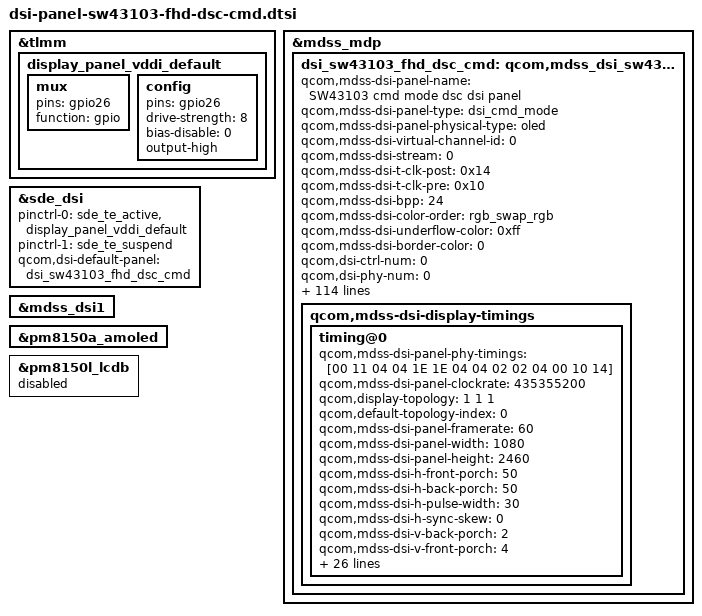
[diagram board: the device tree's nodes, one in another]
/* Copyright (c) 2014, Code Aurora Forum. All rights reserved.
 *
 * This program is free software; you can redistribute it and/or modify
 * it under the terms of the GNU General Public License version 2 and
 * only version 2 as published by the Free Software Foundation.
 *
 * This program is distributed in the hope that it will be useful,
 * but WITHOUT ANY WARRANTY; without even the implied warranty of
 * MERCHANTABILITY or FITNESS FOR A PARTICULAR PURPOSE.  See the
 * GNU General Public License for more details.
 */

&tlmm {
	display_panel_vddi_default: display_panel_vddi_default {
		mux {
			pins = "gpio26";
			function = "gpio";
		};

		config {
			pins = "gpio26";
			drive-strength = <8>;
			bias-disable = <0>;
			output-high;
		};
	};
};

&mdss_mdp {
    dsi_sw43103_fhd_dsc_cmd: qcom,mdss_dsi_sw43103_fhd_dsc_cmd {
		qcom,mdss-dsi-panel-name = "SW43103 cmd mode dsc dsi panel";
		qcom,mdss-dsi-panel-type = "dsi_cmd_mode";
		qcom,mdss-dsi-panel-physical-type = "oled";
		qcom,mdss-dsi-virtual-channel-id = <0>;
		qcom,mdss-dsi-stream = <0>;
		qcom,mdss-dsi-t-clk-post = <0x14>;
		qcom,mdss-dsi-t-clk-pre = <0x10>;
		qcom,mdss-dsi-bpp = <24>;
		qcom,mdss-dsi-color-order = "rgb_swap_rgb";
		qcom,mdss-dsi-underflow-color = <0xff>;
		qcom,mdss-dsi-border-color = <0>;
		qcom,dsi-ctrl-num = <0>;
		qcom,dsi-phy-num = <0>;
		qcom,dsi-select-clocks = "mux_byte_clk0", "mux_pixel_clk0";
		qcom,mdss-dsi-traffic-mode = "burst_mode";
		qcom,mdss-dsi-lane-map = "lane_map_0123";
		qcom,mdss-dsi-bllp-eof-power-mode;
		qcom,mdss-dsi-bllp-power-mode;
		qcom,mdss-dsi-lane-0-state;
		qcom,mdss-dsi-lane-1-state;
		qcom,mdss-dsi-lane-2-state;
		qcom,mdss-dsi-lane-3-state;
		qcom,mdss-dsi-reset-sequence = <1 10>, <0 2>, <1 10>;
		qcom,mdss-dsi-dma-trigger = "trigger_sw";
		qcom,mdss-dsi-mdp-trigger = "none";
		qcom,mdss-dsi-te-pin-select = <1>;
		qcom,panel-te-source = <0>;
		qcom,mdss-dsi-wr-mem-start = <0x2c>;
		qcom,mdss-dsi-wr-mem-continue = <0x3c>;
		qcom,mdss-dsi-te-dcs-command = <1>;
		//qcom,mdss-dsi-te-check-enable;
		//qcom,mdss-dsi-te-using-te-pin;
		//qcom,mdss-dsi-lp11-init;
		qcom,mdss-dsi-tx-eot-append;
		qcom,ulps-enabled;
		qcom,null-insertion-enabled;

		qcom,mdss-pan-physical-width-dimension = <70>;
		qcom,mdss-pan-physical-height-dimension = <159>;

		/* Brightness Map List */
		lge,blmap = <
			0
			6 11 17 22 28 34 39 45 50 56 62 67 73 79 84
			90 95 101 107 112 118 123 129 135 140 146 151 157 163 168
			174 179 185 191 196 202 208 213 219 224 230 236 241 247 252
			258 264 269 275 280 286 292 297 303 308 314 320 325 331 336
			342 348 353 359 365 370 376 381 387 393 398 404 409 415 421
			426 432 437 443 449 454 460 465 471 477 482 488 494 499 505
			510 516 522 527 533 538 544 550 555 561 566 572 578 583 589
			594 600 606 611 617 623 628 634 639 645 651 656 662 667 673
			679 684 690 695 701 707 712 718 723 729 735 740 746 752 757
			763 768 774 780 785 791 796 802 808 813 819 824 830 836 841
			847 852 858 864 869 875 880 886 892 897 903 909 914 920 925
			931 937 942 948 953 959 965 970 976 981 987 993 998 1004 1009
			1015 1021 1026 1032 1038 1043 1049 1054 1060 1066 1071 1077 1082 1088 1094
			1099 1105 1110 1116 1122 1127 1133 1138 1144 1150 1155 1161 1167 1172 1178
			1183 1189 1195 1200 1206 1211 1217 1223 1228 1234 1239 1245 1251 1256 1262
			1267 1273 1279 1284 1290 1295 1301 1307 1312 1318 1324 1329 1335 1340 1346
			1352 1357 1363 1368 1374 1380 1385 1391 1396 1402 1408 1413 1419 1424 1430
			1436 1441 1447 1453 1458 1464 1469 1475 1481 1486 1492 1497 1503 1509 1514
			1520 1525 1531 1537 1542 1548 1553 1559 1565 1570 1576 1582 1587 1593 1598
			1604 1610 1615 1621 1626 1632 1638 1643 1649 1654 1660 1666 1671 1677 1682
			1688 1694 1699 1705 1711 1716 1722 1727 1733 1739 1744 1750 1755 1761 1767
			1772 1778 1783 1789 1795 1800 1806 1811 1817 1823 1828 1834 1839 1845 1851
			1856 1862 1868 1873 1879 1884 1890 1896 1901 1907 1912 1918 1924 1929 1935
			1940 1946 1952 1957 1963 1968 1974 1980 1985 1991 1997 2002 2008 2013 2019
			2025 2030 2036 2041 2047
		>;
		lge,blmap-ve = <
			0
			5 5 5 5 5 5 5 5 5 5 6 8 9 10 11 13 14 15 16 18
			19 20 22 23 24 25 27 28 29 30 32 33 34 35 37 38 43 48 52 57
			62 67 71 76 81 86 90 95 100 105 109 114 119 124 128 133 138 143 147 152
			157 163 168 174 180 185 191 197 202 208 214 219 225 231 236 242 248 253 259 265
			270 273 277 280 293 296 299 302 305 308 312 315 318 321 324 327 330 333 336 339
			342 345 349 352 355 358 361 364 368 371 375 378 382 386 389 393 397 400 404 407
			411 415 418 422 425 429 433 436 440 444 447 451 454 458 467 475 484 492 501 509
			518 522 530 539 547 556 564 573 581 590 599 607 616 624 633 641 650 658 672 680
			687 695 703 711 718 726 734 741 749 757 765 772 780 788 795 803 811 818 826 834
			842 849 857 862 866 871 875 880 884 889 893 898 902 907 912 916 921 925 930 934
			939 943 948 952 957 961 966 971 976 981 986 991 996 1001 1006 1011 1016 1021 1026 1032
			1037 1042 1047 1052 1057 1062 1067 1072 1077 1082 1087 1092 1122 1152 1182 1212 1242 1271 1301 1331
			1361 1391 1421 1451 1481 1511 1541 1571 1601 1630 1660 1690 1720 1750 1780 1782 1783 1785 1786 1788
			1789 1791 1792 1794 1795 1797 1798 1800 1801 1803 1804 1806 1807 1809 1810 1812 1815 1817 1819 1822
			1824 1826 1829 1831 1833 1836 1838 1840 1843 1845 1848 1850 1853 1856 1858 1861 1864 1866 1869 1872
			1874 1877 1880 1882 1885 1888 1890 1893 1896 1898 1901 1904 1906 1909 1912 1914 1917 1920 1922 1925
			1928 1930 1933 1936 1938 1941 1944 1946 1949 1952 1954 1957 1960 1962 1965 1968 1970 1973 1976 1978
			1981 1984 1986 1989 1992 1994 1997 2000 2002 2005 2008 2011 2013 2016 2019 2022 2025 2027 2030 2033
			2036 2039 2041 2044 2047
		>;
		lge,blmap-ex = <
			0
			10 10 10 10 10 10 10 10 127 129 131 133 135 137 139 142 144 146 148 150
			152 154 156 158 160 162 164 166 168 171 173 175 177 179 181 183 189 194 200 205
			211 216 222 227 233 238 244 249 255 261 266 272 277 283 288 294 299 305 310 316
			321 327 333 338 344 349 355 360 366 371 377 382 388 393 399 407 415 423 431 439
			447 455 463 471 479 487 495 503 511 519 527 535 543 551 559 567 575 581 587 594
			600 606 612 619 625 631 637 643 650 656 662 668 675 681 687 695 704 712 721 729
			738 746 754 763 771 780 788 796 805 813 822 830 839 847 847 847 847 847 847 847
			856 866 875 884 893 903 912 921 930 940 949 958 967 977 986 995 1004 1014 1023 1023
			1023 1023 1023 1023 1023 1023 1023 1023 1023 1023 1023 1023 1023 1023 1023 1023 1023 1023 1023 1023
			1023 1023 1023 1023 1023 1023 1023 1023 1023 1023 1023 1023 1023 1023 1023 1023 1023 1023 1023 1023
			1023 1023 1023 1023 1023 1023 1023 1023 1023 1023 1023 1023 1023 1023 1023 1023 1023 1023 1023 1023
			1023 1023 1023 1023 1023 1023 1023 1023 1023 1023 1023 1023 1023 1023 1023 1023 1023 1023 1023 1023
			1023 1023 1023 1023 1023 1023 1023 1023 1023 1023 1023 1023 1023 1023 1023
		>;
		lge,blmap-hdr = <
			0
			5 5 5 5 5 5 5 5 5 5 6 8 9 10 11 13 14 15 16 18
			19 20 22 23 24 25 27 28 29 30 32 33 34 35 37 38 43 48 52 57
			62 67 71 76 81 86 90 95 100 105 109 114 119 124 128 133 138 143 147 152
			157 163 168 174 180 185 191 197 202 208 214 219 225 231 236 242 248 253 259 265
			270 273 277 280 293 296 299 302 305 308 312 315 318 321 324 327 330 333 336 339
			342 345 349 352 355 358 361 364 368 371 375 378 382 386 389 393 397 400 404 407
			411 415 418 422 425 429 433 436 440 444 447 451 454 458 467 475 484 492 501 509
			518 522 530 539 547 556 564 573 581 590 599 607 616 624 633 641 650 658 672 680
			687 695 703 711 718 726 734 741 749 757 765 772 780 788 795 803 811 818 826 834
			842 849 857 862 866 871 875 880 884 889 893 898 902 907 912 916 921 925 930 934
			939 943 948 952 957 961 966 971 976 981 986 991 996 1001 1006 1011 1016 1021 1026 1032
			1037 1042 1047 1052 1057 1062 1067 1072 1077 1082 1087 1092 1122 1152 1182 1212 1242 1271 1301 1331
			1361 1391 1421 1451 1481 1511 1541 1571 1601 1630 1660 1690 1720 1750 1780 1782 1783 1785 1786 1788
			1789 1791 1792 1794 1795 1797 1798 1800 1801 1803 1804 1806 1807 1809 1810 1812 1815 1817 1819 1822
			1824 1826 1829 1831 1833 1836 1838 1840 1843 1845 1848 1850 1853 1856 1858 1861 1864 1866 1869 1872
			1874 1877 1880 1882 1885 1888 1890 1893 1896 1898 1901 1904 1906 1909 1912 1914 1917 1920 1922 1925
			1928 1930 1933 1936 1938 1941 1944 1946 1949 1952 1954 1957 1960 1962 1965 1968 1970 1973 1976 1978
			1981 1984 1986 1989 1992 1994 1997 2000 2002 2005 2008 2011 2013 2016 2019 2022 2025 2027 2030 2033
			2036 2039 2041 2044 2047
		>;

		/* AOD */
		lge,use-ambient;
		lge,aod-interface-data = "partial", "partial", "partial";
		lge,update-pps-in-lp-mode;
		lge,mdss-dsi-nolp-command = [
			05 01 00 00 00 00 01 28
			05 01 00 00 78 00 01 13
			05 01 00 00 00 00 01 29
		];
		lge,mdss-dsi-nolp-command-state = "dsi_lp_mode";
		lge,mdss-dsi-lp2-command = [
			05 01 00 00 00 00 01 28
			05 01 00 00 78 00 01 12
			05 01 00 00 00 00 01 29
		];
		lge,mdss-dsi-lp2-command-state = "dsi_lp_mode";

		lge,use-color-manager;
		lge,color-manager-default-status = <1>;
		lge,mdss-dsi-color-manager-mode-table = <0 1>, <1 1>, <2 1>, <3 1>;

		/* FP LHBM */
		lge,use-fp-lhbm;
		lge,mdss-dsi-fp-lhbm-command = [
			39 01 00 00 00 00 02 B0 A3
			39 01 00 00 00 00 04 EE 02 00 00
			39 01 00 00 00 00 02 B0 A5
			39 01 00 00 00 00 0C CD 10 12 01 5A 90 00 00 00 00 00 62//Green Circle
			39 01 00 00 00 00 02 B0 A1
			39 01 00 00 00 00 0B 55 08 08 72 D4 1C 61 0A 90 04 00//FPS On
			39 01 00 00 00 00 03 51 07 FF
			/*
			mipi.write 0x39 0xCD 0x00 //FP_SHAPE 0: Rectangle
			mipi.write 0x39 0xCD 0x10 //FP_SHAPE 1: circle
			mipi.write 0x39 0xCD 0x10 0x17 //White
			mipi.write 0x39 0xCD 0x00 0x14 //Red
			mipi.write 0x39 0xCD 0x00 0x12 //Green
			mipi.write 0x39 0xCD 0x00 0x11 //Blue
			mipi.write 0x39 0xCD 0x00 0x00 //Black
			*/
		];
		lge,mdss-dsi-fp-lhbm-command-state = "dsi_hs_mode";

		lge,mdss-dsi-fp-lhbm-exit-command = [
			39 01 00 00 00 00 02 B0 A1
			39 01 00 00 00 00 0B 55 08 00 //FPS Off
			39 01 00 00 00 00 03 51 06 F4
		];
		lge,mdss-dsi-fp-lhbm-exit-command-state = "dsi_hs_mode";

		/* Screen Color Control */
		lge,mdss-dsi-disp-ctrl-command-1 = [
		    15 01 00 00 00 00 02 B0 A1
			15 01 00 00 00 00 02 53 00
		];
		lge,mdss-dsi-disp-ctrl-command-1-state = "dsi_hs_mode";

		lge,mdss-dsi-wb-default-command = [
			15 01 00 00 00 00 02 B0 A4
			39 01 00 00 00 00 0B B4 00 03 05 AF 03 05 AF 03 05 AF
			39 01 00 00 00 00 1C B5 00 FF 80 00 80 00 80 00 80 00 FF 80 00 80 00 80 00 80 00 FF 80 00 80 00 80 00 80
		];
		lge,mdss-dsi-wb-default-command-state = "dsi_hs_mode";

		lge,digital-gamma-cmds-dummy = [
			15 01 00 00 00 00 02 B0 A4
			39 01 00 00 00 00 0B B4 00 03 05 AF 03 05 AF 03 05 AF
			39 01 00 00 00 00 1C B5 00 FF 80 00 80 00 80 00 80 00 FF 80 00 80 00 80 00 80 00 FF 80 00 80 00 80 00 80
		];
		lge,digital-gamma-cmds-dummy-command = "dsi_hs_mode";

		lge,mdss-dsi-saturation-command = [
		    15 01 00 00 00 00 02 B0 A4
			39 01 00 00 00 00 0D B7 80 80 80 80 80 80 80 80 80 80 80 80
			39 01 00 00 00 00 0D B8 80 80 80 80 80 80 80 80 80 80 80 80
			39 01 00 00 00 00 0D B9 40 40 40 3A 3A 3D 40 40 40 40 40 40
			39 01 00 00 00 00 0D BA 80 80 80 80 80 80 80 80 80 80 80 80
		];
		lge,mdss-dsi-saturation-command-state = "dsi_hs_mode";

		lge,mdss-dsi-hue-command = [
		    15 01 00 00 00 00 02 B0 A4
			39 01 00 00 00 00 0D BB 80 80 80 80 80 80 80 80 80 80 80 80
		];
		lge,mdss-dsi-hue-command-state = "dsi_hs_mode";

		lge,mdss-dsi-sharpness-command = [
		    15 01 00 00 00 00 02 B0 A4
			39 01 00 00 00 00 0C B2 89 1F 1F 88 24 68 22 20 04 00 00
		];
		lge,mdss-dsi-sharpness-command-state = "dsi_hs_mode";

		lge,mdss-dsi-cm-cinema = [
			15 01 00 00 00 00 02 B0 A4
			39 01 00 00 00 00 0B B4 00 03 05 AF 03 01 6B 03 01 6B
			39 01 00 00 00 00 1C B5 00 FF 80 00 80 00 80 00 80 00 F2 7E FC 7B F9 78 F6 75 00 C9 79 F2 6B E4 5E D7 50
			39 01 00 00 00 00 0D B7 80 80 80 80 80 80 80 80 80 80 80 80
			39 01 00 00 00 00 0D B8 80 80 80 80 89 80 80 80 80 80 80 80
			39 01 00 00 00 00 0D B9 2F 2D 2D 37 3D 35 3A 3A 3A 3A 35 2E
			39 01 00 00 00 00 0D BA 80 80 80 80 88 80 80 80 80 80 80 7D
			39 01 00 00 00 00 0D BB 5D 5A 7B 8B 75 70 80 80 80 80 83 8C
		];
		lge,mdss-dsi-cm-cinema-state = "dsi_hs_mode";

		lge,mdss-dsi-cm-sports = [
			15 01 00 00 00 00 02 B0 A4
			39 01 00 00 00 00 0B B4 00 03 01 6B 03 01 6B 03 05 AF
			39 01 00 00 00 00 1C B5 00 DD 7B F7 73 EF 6A E6 62 00 F2 7E FC 7B F9 78 F6 75 00 FF 80 00 80 00 80 00 80
		];
		lge,mdss-dsi-cm-sports-state = "dsi_hs_mode";

		lge,mdss-dsi-cm-game = [
			15 01 00 00 00 00 02 B0 A4
			39 01 00 00 00 00 0B B4 00 03 01 6B 03 01 6B 03 05 AF
			39 01 00 00 00 00 1C B5 00 F0 7E FC 7A F8 76 F4 72 00 FB 7F FF 7E FE 7E FD 7D 00 FF 80 00 80 00 80 00 80
		];
		lge,mdss-dsi-cm-game-state = "dsi_hs_mode";

		lge,mdss-dsi-cm-photo = [
			15 01 00 00 00 00 02 B0 A4
			39 01 00 00 00 00 0B B4 00 03 05 AF 03 01 6B 03 01 6B
			39 01 00 00 00 00 1C B5 00 FF 80 00 80 00 80 00 80 00 F2 7E FC 7B F9 78 F6 75 00 C9 79 F2 6B E4 5E D7 50
			39 01 00 00 00 00 0D B7 80 80 80 80 80 80 80 80 80 80 80 80
			39 01 00 00 00 00 0D B8 80 80 7D 78 80 80 80 80 80 80 80 80
			39 01 00 00 00 00 0D B9 25 2A 2D 2D 2F 4D 2D 3B 40 40 40 40
			39 01 00 00 00 00 0D BA 76 6C 6C 6D 6D 80 70 80 80 80 80 80
			39 01 00 00 00 00 0D BB 65 4D 62 78 78 78 80 6D 6D 80 80 80
		];
		lge,mdss-dsi-cm-photo-state = "dsi_hs_mode";

		lge,mdss-dsi-cm-web = [
			15 01 00 00 00 00 02 B0 A4
			39 01 00 00 00 00 0B B4 00 03 05 AF 03 01 6B 03 01 6B
			39 01 00 00 00 00 1C B5 00 FF 80 00 80 00 80 00 80 00 F2 7E FC 7B F9 78 F6 75 00 C9 79 F2 6B E4 5E D7 50
			39 01 00 00 00 00 0D B7 80 80 80 80 80 80 80 80 80 80 80 80
			39 01 00 00 00 00 0D B8 80 80 80 80 80 80 80 80 80 80 80 80
			39 01 00 00 00 00 0D B9 25 29 27 26 27 39 35 2F 2B 2B 20 28
			39 01 00 00 00 00 0D BA 79 70 70 70 75 70 70 70 63 63 63 63
			39 01 00 00 00 00 0D BB 66 70 8A 8A 67 67 80 95 95 80 8B 78
		];
		lge,mdss-dsi-cm-web-state = "dsi_hs_mode";

		/* Video Enahnacement */
		lge,mdss-dsi-ve-on-command = [
		    15 01 00 00 00 00 02 B0 A1
			15 01 00 00 00 00 02 53 14
			39 01 00 00 00 00 02 55 28
			15 01 00 00 00 00 02 B0 A4
			39 01 00 00 00 00 0C B2 89 3F 2F 88 88 88 22 20 04 00 00
			39 01 00 00 00 00 0D B7 80 80 80 80 80 80 80 80 80 80 80 80
			39 01 00 00 00 00 0D B8 80 80 80 80 80 80 80 80 80 80 80 80
			39 01 00 00 00 00 0D B9 46 46 46 46 46 46 46 46 46 46 46 46
			39 01 00 00 00 00 0D BA 80 80 80 80 80 80 80 80 80 80 80 80
			39 01 00 00 00 00 0D BB 80 80 80 80 80 80 80 80 80 80 80 80
		];
		lge,mdss-dsi-ve-on-command-state = "dsi_hs_mode";

		lge,mdss-dsi-ve-off-command = [
		    15 01 00 00 00 00 02 B0 A1
			39 01 00 00 00 00 02 55 08
		];
		lge,mdss-dsi-ve-off-command-state = "dsi_hs_mode";

		lge,use-irc-ctrl;
		lge,mdss-dsi-irc-command = [
			15 01 00 00 00 00 02 B0 A5
			39 01 00 00 00 00 08 B1 60 C0 00 00 00 10 FF
		];
		lge,mdss-dsi-irc-command-state = "dsi_hs_mode";

		lge,use-ace-ctrl;
		lge,default-ace-mode = <0>;
		lge,mdss-dsi-ace-tune-command = [
			15 01 00 00 00 00 02 B0 A4
			39 01 00 00 00 00 0C B2 89 3F 2F 88 88 88 33 20 04 00 00
			39 01 00 00 00 00 07 B3 00 80 FF 88 08 93
			15 01 00 00 00 00 02 B0 A1
			15 01 00 00 00 00 02 53 14
			39 01 00 00 00 00 02 55 28
		];
		lge,mdss-dsi-ace-restore-command = [
			15 01 00 00 00 00 02 B0 A1
			15 01 00 00 00 00 02 53 00
			39 01 00 00 00 00 02 55 08
		];
		lge,mdss-dsi-ace-command-state = "dsi_hs_mode";

		lge,use-touch-vsync-enable;
		lge,mdss-dsi-touch-vsync-enable-command = [
			15 01 00 00 00 00 02 B0 A6
			39 01 00 00 00 00 05 FC 00 00 41 40
		];
		lge,mdss-dsi-touch-vsync-enable-command-state = "dsi_hs_mode";

		qcom,mdss-dsi-display-timings {
			timing@0{
				qcom,mdss-dsi-panel-phy-timings = [00 11 04 04 1E 1E 04 04 02 02 04 00 10 14];
				qcom,mdss-dsi-panel-clockrate = <435355200>;
				qcom,display-topology = <1 1 1>;
				qcom,default-topology-index = <0>;
				qcom,mdss-dsi-panel-framerate = <60>;
				qcom,mdss-dsi-panel-width = <1080>;
				qcom,mdss-dsi-panel-height = <2460>;
				qcom,mdss-dsi-h-front-porch = <50>;
				qcom,mdss-dsi-h-back-porch = <50>;
				qcom,mdss-dsi-h-pulse-width = <30>;
				qcom,mdss-dsi-h-sync-skew = <0>;
				qcom,mdss-dsi-v-back-porch = <2>;
				qcom,mdss-dsi-v-front-porch = <4>;
				qcom,mdss-dsi-v-pulse-width = <2>;
				qcom,mdss-dsi-h-left-border = <0>;
				qcom,mdss-dsi-h-right-border = <0>;
				qcom,mdss-dsi-v-top-border = <0>;
				qcom,mdss-dsi-v-bottom-border = <0>;
				qcom,mdss-dsi-h-sync-pulse = <0>;
				//qcom,mdss-mdp-transfer-time-us = <15000>;

				qcom,mdss-dsi-on-command = [
					15 01 00 00 00 00 02 B0 A1
					15 01 00 00 00 00 02 53 00
					15 01 00 00 00 00 02 55 08
					15 01 00 00 00 00 02 3D 00
					15 01 00 00 00 00 02 35 00
					39 01 00 00 00 00 05 2A 00 00 04 37
					39 01 00 00 00 00 05 2B 00 00 09 9B
					39 01 00 00 00 00 05 30 00 00 09 9B
					39 01 00 00 00 00 05 31 00 00 04 37

					//IP Setting
					15 01 00 00 00 00 02 B0 A6 //level6 TOP_CTRL
					15 01 00 00 00 00 02 F7 AC //OTP auto load off afet Sleep out
					15 01 00 00 00 00 02 B0 A1 //level1TOP_CTRL
					15 01 00 00 00 00 02 B0 CA //Manufacturer Command Protect
					05 01 00 00 78 00 01 11    //Sleep Out

					15 01 00 00 00 00 02 B0 A6
					39 01 00 00 00 00 05 FC 00 00 41 40		//Touch Vsync_enable

					15 01 00 00 00 00 02 B0 A1 //level1TOP_CTRL
					15 01 00 00 00 00 02 53 00 //Digital Gamma & Sharpness & BC Dimming & Contrast & CM Mode0 OFF

					15 01 00 00 00 00 02 B0 A1
					39 01 00 00 00 00 03 55 08 00 //HDR Mode1 & HBM Mode2 & ACL set1 & ICC set1 & FPS OFF

					/* TODO : Check SW43103 A2 panel.
					15 01 00 00 00 00 02 B0 A1
					15 01 00 00 00 00 02 3D 08 //DEMURA Enable
					*/

					15 01 00 00 00 00 02 B0 A4
					15 01 00 00 00 00 02 B1 05
					15 01 00 00 00 00 02 B0 A1 //PPA & EPP & Sharpening ON

					15 01 00 00 00 00 02 B0 A5
					15 01 00 00 00 00 02 C0 00
					15 01 00 00 00 00 02 B0 A1 //Corner & Notch OFF

					15 01 00 00 00 00 02 B0 A5
					39 01 00 00 00 00 03 D2 F1 50
					15 01 00 00 78 00 02 B0 A1 //Data Remapping (ON)

					/* For only Bringup A2 D-IC
					00 00 00 00 12 C1 88 48 60 0F 51 50 50 34 4F 5A 33 06 54 54 11 11 02
					39 01 00 00 00 00 1F C3 1B 23 26 26 26 26 26 26 26 26 1B 23 26 26 26 26 26 26 26 26 1B 23 26 26 26 26 26 26 26 26
					*/
					/* DCC(GCC) off */
                                       15 01 00 00 00 00 02 B0 A1
                                       39 01 00 00 00 00 06 C2 F3 20 00 00 1D
                                       15 01 00 00 00 00 02 B0 A5
                                       39 01 00 00 00 00 04 D1 0A 00 01
                                       39 01 00 00 14 00 04 D1 02 00 01
                                       39 01 00 00 00 00 04 D1 00 00 01

					05 01 00 00 78 00 01 29 //Display On
					39 01 00 00 00 00 03 51 06 F4
					];

				qcom,mdss-dsi-post-panel-on-command = [
					//05 01 00 00 78 00 01 12
					//39 01 00 00 00 00 03 51 07 FF
				];

				qcom,mdss-dsi-off-command = [
					05 01 00 00 78 00 01 28
					05 01 00 00 96 00 01 10
				];

				qcom,compression-mode = "dsc";
				qcom,mdss-dsc-version = <0x11>;
				qcom,mdss-dsc-scr-version = <0x1>;
				qcom,mdss-dsc-slice-height = <60>;
				qcom,mdss-dsc-slice-width = <540>;
				qcom,mdss-dsc-slice-per-pkt = <2>;
				qcom,mdss-dsc-bit-per-component = <8>;
				qcom,mdss-dsc-bit-per-pixel = <8>;
				qcom,lm-split = <540 540>;
				qcom,mdss-dsc-encoders = <2>;
				qcom,mdss-dsc-block-prediction-enable;

				qcom,mdss-dsi-on-command-state = "dsi_lp_mode";
				qcom,mdss-dsi-off-command-state = "dsi_lp_mode";

				qcom,mode-control-dsi-state = "dsi_lp_mode";
				qcom,mdss-dsi-pps-command-state = "dsi_lp_mode";
			};
		};
	};
};

&sde_dsi  {
	pinctrl-names = "panel_active", "panel_suspend";
	pinctrl-0 = <&sde_te_active &display_panel_vddi_default>;
	pinctrl-1 = <&sde_te_suspend>;
	qcom,dsi-default-panel = <&dsi_sw43103_fhd_dsc_cmd>;
};

&mdss_dsi1 {
	status = "ok";
};


&pm8150a_amoled {
    status = "ok";
};

&pm8150l_lcdb {
    status = "disabled";
};

